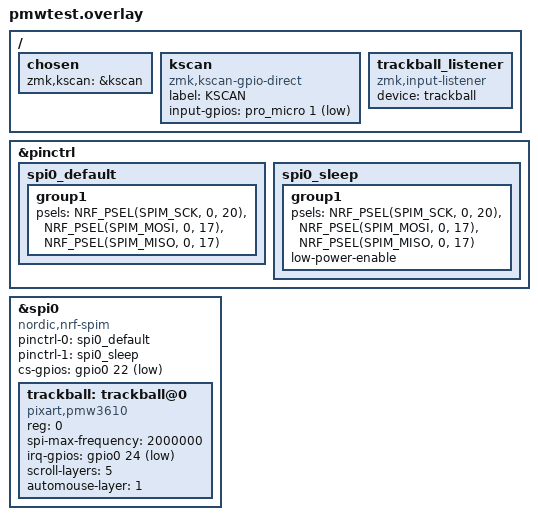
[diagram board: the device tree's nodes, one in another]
/ {
    chosen {
        zmk,kscan = &kscan;
    };

    kscan: kscan {
        compatible = "zmk,kscan-gpio-direct";
        label = "KSCAN";
        input-gpios = 
            <&pro_micro 1 (GPIO_ACTIVE_LOW | GPIO_PULL_UP)>;
    };

  trackball_listener {
    compatible = "zmk,input-listener";
    device = <&trackball>;

  };
};


&pinctrl {
    spi0_default: spi0_default {
        group1 {
            psels = <NRF_PSEL(SPIM_SCK, 0, 20)>,
                <NRF_PSEL(SPIM_MOSI, 0, 17)>,
                <NRF_PSEL(SPIM_MISO, 0, 17)>;
        };
    };

    spi0_sleep: spi0_sleep {
        group1 {
            psels = <NRF_PSEL(SPIM_SCK, 0, 20)>,
                <NRF_PSEL(SPIM_MOSI, 0, 17)>,
                <NRF_PSEL(SPIM_MISO, 0, 17)>;
            low-power-enable;
        };
    };
};

&spi0 {
    status = "okay";
    compatible = "nordic,nrf-spim";
    pinctrl-0 = <&spi0_default>;
    pinctrl-1 = <&spi0_sleep>;
    pinctrl-names = "default", "sleep";
    cs-gpios = <&gpio0 22 GPIO_ACTIVE_LOW>;

    trackball: trackball@0 {
        status = "okay";
        compatible = "pixart,pmw3610";
        reg = <0>;
        spi-max-frequency = <2000000>;
        irq-gpios = <&gpio0 24 (GPIO_ACTIVE_LOW | GPIO_PULL_UP)>;
         /*   optional features   */
        scroll-layers = <5>;
        automouse-layer = <1>;
        // snipe-layers = <1>;
    };
};

